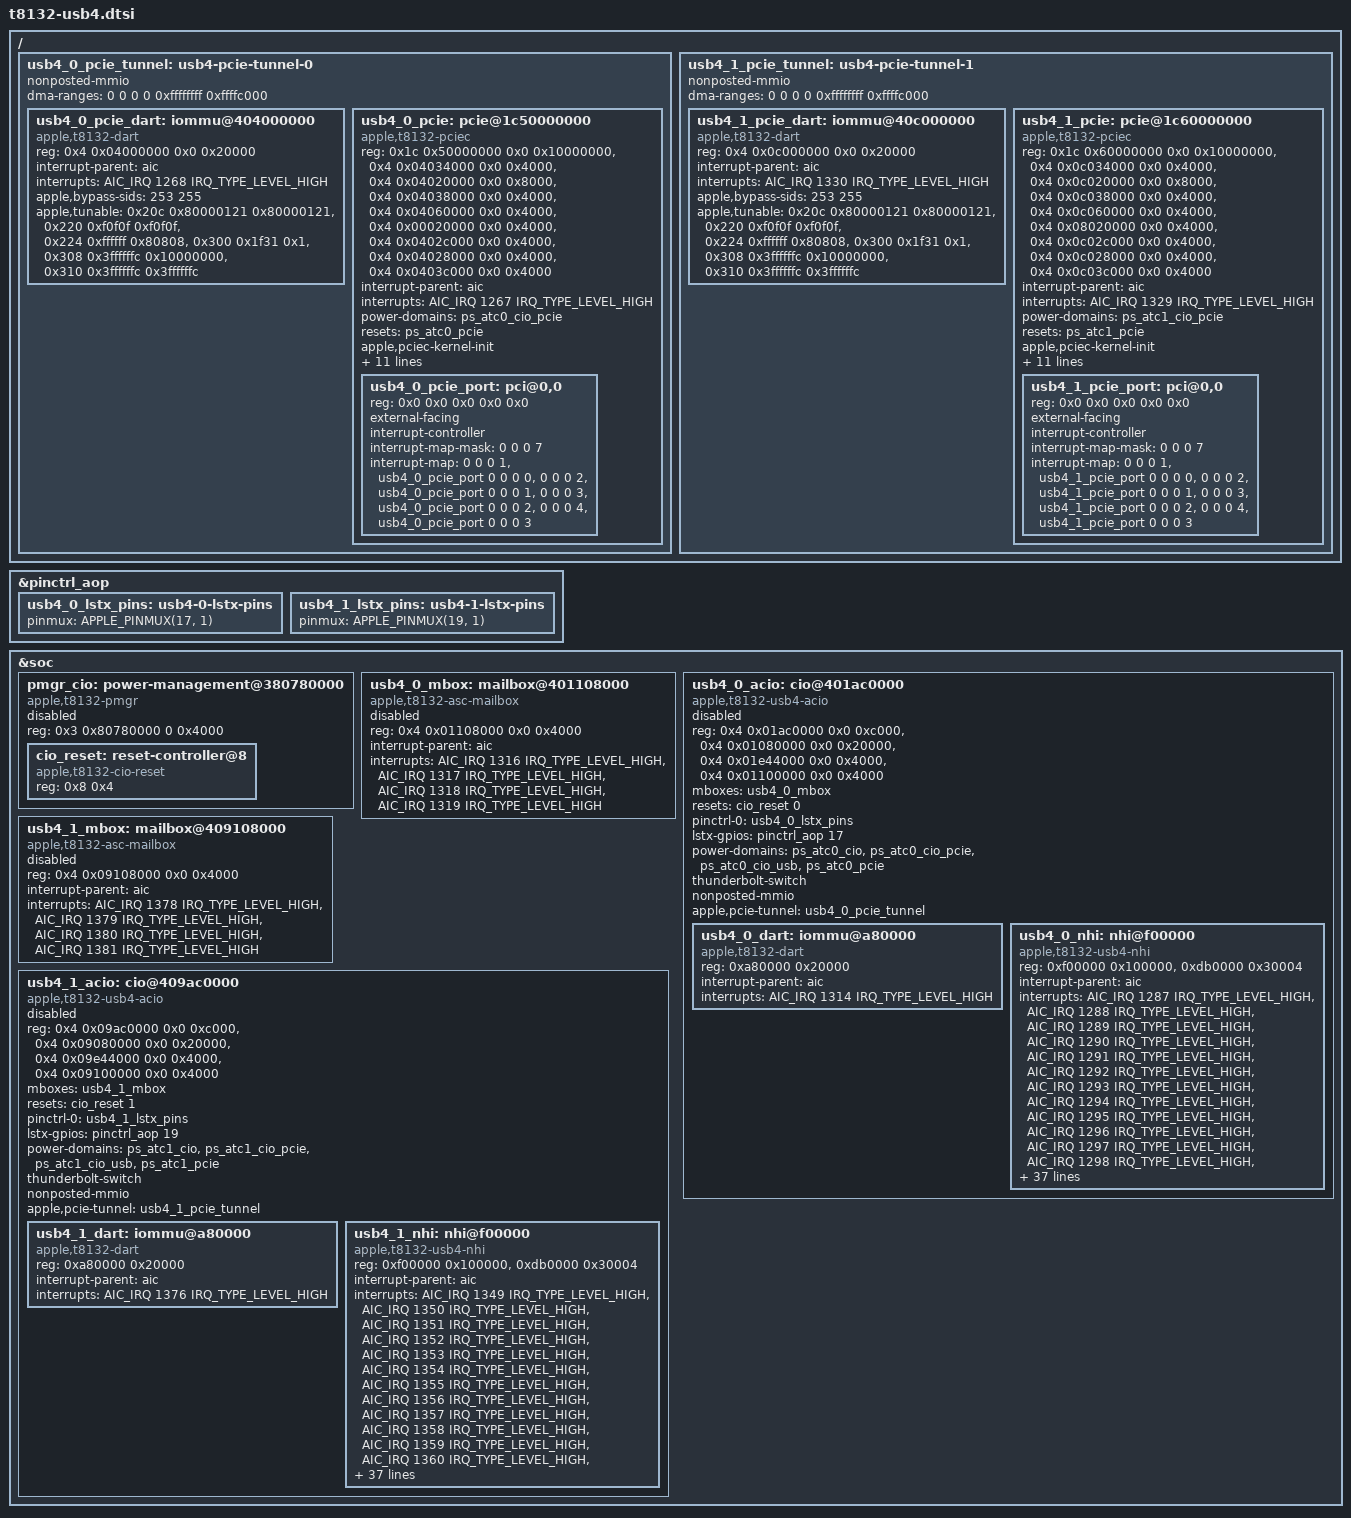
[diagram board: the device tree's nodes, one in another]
// SPDX-License-Identifier: GPL-2.0+ OR MIT
/*
 * Apple T8132 (M4) USB4/Thunderbolt host routers: ACIO0 behind ATC0, ACIO1 behind ATC1.
 *
 * The layout follows T6030: the same offsets from the ACIO base for the rc, sram,
 * PCIe adapter, MxWrap CPU, mailbox, DART and NHI blocks. ACIO1 sits 0x8000000 above
 * ACIO0 and its interrupts 62 above. The NHI ring interrupts are listed tx first
 * (the lower block), then rx.
 *
 * The boot loader fills apple,tunable-rc, -pcie-adapter, -nhi and
 * apple,thunderbolt-drom through the usb4-N-* aliases of the board.
 */

&pinctrl_aop {
	/* LSTX, handed to each router once it is up and held as a GPIO while it is off. */
	usb4_0_lstx_pins: usb4-0-lstx-pins {
		pinmux = <APPLE_PINMUX(17, 1)>;
	};

	usb4_1_lstx_pins: usb4-1-lstx-pins {
		pinmux = <APPLE_PINMUX(19, 1)>;
	};
};

&soc {
	pmgr_cio: power-management@380780000 {
		compatible = "apple,t8132-pmgr", "apple,t8103-pmgr", "syscon", "simple-mfd";
		#address-cells = <1>;
		#size-cells = <1>;
		reg = <0x3 0x80780000 0 0x4000>;
		status = "disabled";

		cio_reset: reset-controller@8 {
			compatible = "apple,t8132-cio-reset", "apple,t6000-cio-reset";
			reg = <0x8 0x4>;
			#reset-cells = <1>;
		};
	};

	usb4_0_mbox: mailbox@401108000 {
		compatible = "apple,t8132-asc-mailbox", "apple,asc-mailbox-v4";
		reg = <0x4 0x01108000 0x0 0x4000>;
		interrupt-parent = <&aic>;
		interrupts = <AIC_IRQ 1316 IRQ_TYPE_LEVEL_HIGH>,
			     <AIC_IRQ 1317 IRQ_TYPE_LEVEL_HIGH>,
			     <AIC_IRQ 1318 IRQ_TYPE_LEVEL_HIGH>,
			     <AIC_IRQ 1319 IRQ_TYPE_LEVEL_HIGH>;
		interrupt-names = "send-empty", "send-not-empty",
				  "recv-empty", "recv-not-empty";
		#mbox-cells = <0>;
		status = "disabled";
	};

	usb4_0_acio: cio@401ac0000 {
		compatible = "apple,t8132-usb4-acio", "apple,t8103-usb4-acio";
		reg = <0x4 0x01ac0000 0x0 0xc000>,
		      <0x4 0x01080000 0x0 0x20000>,
		      <0x4 0x01e44000 0x0 0x4000>,
		      <0x4 0x01100000 0x0 0x4000>;
		reg-names = "rc", "sram", "pcie-adapter", "cpu";

		mboxes = <&usb4_0_mbox>;
		resets = <&cio_reset 0>;
		pinctrl-names = "lstx";
		pinctrl-0 = <&usb4_0_lstx_pins>;
		lstx-gpios = <&pinctrl_aop 17 GPIO_ACTIVE_HIGH>;

		power-domains = <&ps_atc0_cio>,
				<&ps_atc0_cio_pcie>,
				<&ps_atc0_cio_usb>;

		thunderbolt-switch;

		#address-cells = <1>;
		#size-cells = <1>;
		ranges = <0x0 0x4 0x01000000 0x1000000>;
		nonposted-mmio;
		status = "disabled";

		usb4_0_dart: iommu@a80000 {
			compatible = "apple,t8132-dart", "apple,t8110-dart";
			reg = <0xa80000 0x20000>;
			interrupt-parent = <&aic>;
			interrupts = <AIC_IRQ 1314 IRQ_TYPE_LEVEL_HIGH>;
			#iommu-cells = <5>;
		};

		usb4_0_nhi: nhi@f00000 {
			compatible = "apple,t8132-usb4-nhi", "apple,t8103-usb4-nhi";
			reg = <0xf00000 0x100000>,
			      <0xdb0000 0x30004>;
			reg-names = "nhi", "pdf";
			interrupt-parent = <&aic>;
			interrupts = <AIC_IRQ 1287 IRQ_TYPE_LEVEL_HIGH>,
				     <AIC_IRQ 1288 IRQ_TYPE_LEVEL_HIGH>,
				     <AIC_IRQ 1289 IRQ_TYPE_LEVEL_HIGH>,
				     <AIC_IRQ 1290 IRQ_TYPE_LEVEL_HIGH>,
				     <AIC_IRQ 1291 IRQ_TYPE_LEVEL_HIGH>,
				     <AIC_IRQ 1292 IRQ_TYPE_LEVEL_HIGH>,
				     <AIC_IRQ 1293 IRQ_TYPE_LEVEL_HIGH>,
				     <AIC_IRQ 1294 IRQ_TYPE_LEVEL_HIGH>,
				     <AIC_IRQ 1295 IRQ_TYPE_LEVEL_HIGH>,
				     <AIC_IRQ 1296 IRQ_TYPE_LEVEL_HIGH>,
				     <AIC_IRQ 1297 IRQ_TYPE_LEVEL_HIGH>,
				     <AIC_IRQ 1298 IRQ_TYPE_LEVEL_HIGH>,
				     <AIC_IRQ 1299 IRQ_TYPE_LEVEL_HIGH>,
				     <AIC_IRQ 1300 IRQ_TYPE_LEVEL_HIGH>,
				     <AIC_IRQ 1301 IRQ_TYPE_LEVEL_HIGH>,
				     <AIC_IRQ 1302 IRQ_TYPE_LEVEL_HIGH>,
				     <AIC_IRQ 1303 IRQ_TYPE_LEVEL_HIGH>,
				     <AIC_IRQ 1304 IRQ_TYPE_LEVEL_HIGH>,
				     <AIC_IRQ 1305 IRQ_TYPE_LEVEL_HIGH>,
				     <AIC_IRQ 1306 IRQ_TYPE_LEVEL_HIGH>,
				     <AIC_IRQ 1307 IRQ_TYPE_LEVEL_HIGH>,
				     <AIC_IRQ 1308 IRQ_TYPE_LEVEL_HIGH>,
				     <AIC_IRQ 1309 IRQ_TYPE_LEVEL_HIGH>,
				     <AIC_IRQ 1310 IRQ_TYPE_LEVEL_HIGH>;
			interrupt-names =
				"txring0", "txring1", "txring2",
				"txring3", "txring4", "txring5",
				"txring6", "txring7", "txring8",
				"txring9", "txring10", "txring11",
				"rxring0", "rxring1", "rxring2",
				"rxring3", "rxring4", "rxring5",
				"rxring6", "rxring7", "rxring8",
				"rxring9", "rxring10", "rxring11";
			iommus = <&usb4_0_dart 0 0x100 0x0 0x10 0x0>,
				 <&usb4_0_dart 1 0x100 0x0 0x10 0x0>,
				 <&usb4_0_dart 2 0x100 0x0 0x10 0x0>,
				 <&usb4_0_dart 3 0x100 0x0 0x10 0x0>,
				 <&usb4_0_dart 4 0x100 0x0 0x10 0x0>,
				 <&usb4_0_dart 5 0x100 0x0 0x10 0x0>,
				 <&usb4_0_dart 6 0x100 0x0 0x10 0x0>,
				 <&usb4_0_dart 7 0x100 0x0 0x10 0x0>,
				 <&usb4_0_dart 8 0x100 0x0 0x10 0x0>,
				 <&usb4_0_dart 9 0x100 0x0 0x10 0x0>,
				 <&usb4_0_dart 10 0x100 0x0 0x10 0x0>,
				 <&usb4_0_dart 11 0x100 0x0 0x10 0x0>,
				 <&usb4_0_dart 16 0x100 0x0 0x10 0x0>,
				 <&usb4_0_dart 17 0x100 0x0 0x10 0x0>,
				 <&usb4_0_dart 18 0x100 0x0 0x10 0x0>,
				 <&usb4_0_dart 19 0x100 0x0 0x10 0x0>,
				 <&usb4_0_dart 20 0x100 0x0 0x10 0x0>,
				 <&usb4_0_dart 21 0x100 0x0 0x10 0x0>,
				 <&usb4_0_dart 22 0x100 0x0 0x10 0x0>,
				 <&usb4_0_dart 23 0x100 0x0 0x10 0x0>,
				 <&usb4_0_dart 24 0x100 0x0 0x10 0x0>,
				 <&usb4_0_dart 25 0x100 0x0 0x10 0x0>,
				 <&usb4_0_dart 26 0x100 0x0 0x10 0x0>,
				 <&usb4_0_dart 27 0x100 0x0 0x10 0x0>;
			/* To be filled by the loader */
			apple,thunderbolt-drom = [00];
		};
	};

	usb4_1_mbox: mailbox@409108000 {
		compatible = "apple,t8132-asc-mailbox", "apple,asc-mailbox-v4";
		reg = <0x4 0x09108000 0x0 0x4000>;
		interrupt-parent = <&aic>;
		interrupts = <AIC_IRQ 1378 IRQ_TYPE_LEVEL_HIGH>,
			     <AIC_IRQ 1379 IRQ_TYPE_LEVEL_HIGH>,
			     <AIC_IRQ 1380 IRQ_TYPE_LEVEL_HIGH>,
			     <AIC_IRQ 1381 IRQ_TYPE_LEVEL_HIGH>;
		interrupt-names = "send-empty", "send-not-empty",
				  "recv-empty", "recv-not-empty";
		#mbox-cells = <0>;
		status = "disabled";
	};

	usb4_1_acio: cio@409ac0000 {
		compatible = "apple,t8132-usb4-acio", "apple,t8103-usb4-acio";
		reg = <0x4 0x09ac0000 0x0 0xc000>,
		      <0x4 0x09080000 0x0 0x20000>,
		      <0x4 0x09e44000 0x0 0x4000>,
		      <0x4 0x09100000 0x0 0x4000>;
		reg-names = "rc", "sram", "pcie-adapter", "cpu";

		mboxes = <&usb4_1_mbox>;
		resets = <&cio_reset 1>;
		pinctrl-names = "lstx";
		pinctrl-0 = <&usb4_1_lstx_pins>;
		lstx-gpios = <&pinctrl_aop 19 GPIO_ACTIVE_HIGH>;

		power-domains = <&ps_atc1_cio>,
				<&ps_atc1_cio_pcie>,
				<&ps_atc1_cio_usb>;

		thunderbolt-switch;

		#address-cells = <1>;
		#size-cells = <1>;
		ranges = <0x0 0x4 0x09000000 0x1000000>;
		nonposted-mmio;
		status = "disabled";

		usb4_1_dart: iommu@a80000 {
			compatible = "apple,t8132-dart", "apple,t8110-dart";
			reg = <0xa80000 0x20000>;
			interrupt-parent = <&aic>;
			interrupts = <AIC_IRQ 1376 IRQ_TYPE_LEVEL_HIGH>;
			#iommu-cells = <5>;
		};

		usb4_1_nhi: nhi@f00000 {
			compatible = "apple,t8132-usb4-nhi", "apple,t8103-usb4-nhi";
			reg = <0xf00000 0x100000>,
			      <0xdb0000 0x30004>;
			reg-names = "nhi", "pdf";
			interrupt-parent = <&aic>;
			interrupts = <AIC_IRQ 1349 IRQ_TYPE_LEVEL_HIGH>,
				     <AIC_IRQ 1350 IRQ_TYPE_LEVEL_HIGH>,
				     <AIC_IRQ 1351 IRQ_TYPE_LEVEL_HIGH>,
				     <AIC_IRQ 1352 IRQ_TYPE_LEVEL_HIGH>,
				     <AIC_IRQ 1353 IRQ_TYPE_LEVEL_HIGH>,
				     <AIC_IRQ 1354 IRQ_TYPE_LEVEL_HIGH>,
				     <AIC_IRQ 1355 IRQ_TYPE_LEVEL_HIGH>,
				     <AIC_IRQ 1356 IRQ_TYPE_LEVEL_HIGH>,
				     <AIC_IRQ 1357 IRQ_TYPE_LEVEL_HIGH>,
				     <AIC_IRQ 1358 IRQ_TYPE_LEVEL_HIGH>,
				     <AIC_IRQ 1359 IRQ_TYPE_LEVEL_HIGH>,
				     <AIC_IRQ 1360 IRQ_TYPE_LEVEL_HIGH>,
				     <AIC_IRQ 1361 IRQ_TYPE_LEVEL_HIGH>,
				     <AIC_IRQ 1362 IRQ_TYPE_LEVEL_HIGH>,
				     <AIC_IRQ 1363 IRQ_TYPE_LEVEL_HIGH>,
				     <AIC_IRQ 1364 IRQ_TYPE_LEVEL_HIGH>,
				     <AIC_IRQ 1365 IRQ_TYPE_LEVEL_HIGH>,
				     <AIC_IRQ 1366 IRQ_TYPE_LEVEL_HIGH>,
				     <AIC_IRQ 1367 IRQ_TYPE_LEVEL_HIGH>,
				     <AIC_IRQ 1368 IRQ_TYPE_LEVEL_HIGH>,
				     <AIC_IRQ 1369 IRQ_TYPE_LEVEL_HIGH>,
				     <AIC_IRQ 1370 IRQ_TYPE_LEVEL_HIGH>,
				     <AIC_IRQ 1371 IRQ_TYPE_LEVEL_HIGH>,
				     <AIC_IRQ 1372 IRQ_TYPE_LEVEL_HIGH>;
			interrupt-names =
				"txring0", "txring1", "txring2",
				"txring3", "txring4", "txring5",
				"txring6", "txring7", "txring8",
				"txring9", "txring10", "txring11",
				"rxring0", "rxring1", "rxring2",
				"rxring3", "rxring4", "rxring5",
				"rxring6", "rxring7", "rxring8",
				"rxring9", "rxring10", "rxring11";
			iommus = <&usb4_1_dart 0 0x100 0x0 0x10 0x0>,
				 <&usb4_1_dart 1 0x100 0x0 0x10 0x0>,
				 <&usb4_1_dart 2 0x100 0x0 0x10 0x0>,
				 <&usb4_1_dart 3 0x100 0x0 0x10 0x0>,
				 <&usb4_1_dart 4 0x100 0x0 0x10 0x0>,
				 <&usb4_1_dart 5 0x100 0x0 0x10 0x0>,
				 <&usb4_1_dart 6 0x100 0x0 0x10 0x0>,
				 <&usb4_1_dart 7 0x100 0x0 0x10 0x0>,
				 <&usb4_1_dart 8 0x100 0x0 0x10 0x0>,
				 <&usb4_1_dart 9 0x100 0x0 0x10 0x0>,
				 <&usb4_1_dart 10 0x100 0x0 0x10 0x0>,
				 <&usb4_1_dart 11 0x100 0x0 0x10 0x0>,
				 <&usb4_1_dart 16 0x100 0x0 0x10 0x0>,
				 <&usb4_1_dart 17 0x100 0x0 0x10 0x0>,
				 <&usb4_1_dart 18 0x100 0x0 0x10 0x0>,
				 <&usb4_1_dart 19 0x100 0x0 0x10 0x0>,
				 <&usb4_1_dart 20 0x100 0x0 0x10 0x0>,
				 <&usb4_1_dart 21 0x100 0x0 0x10 0x0>,
				 <&usb4_1_dart 22 0x100 0x0 0x10 0x0>,
				 <&usb4_1_dart 23 0x100 0x0 0x10 0x0>,
				 <&usb4_1_dart 24 0x100 0x0 0x10 0x0>,
				 <&usb4_1_dart 25 0x100 0x0 0x10 0x0>,
				 <&usb4_1_dart 26 0x100 0x0 0x10 0x0>,
				 <&usb4_1_dart 27 0x100 0x0 0x10 0x0>;
			/* To be filled by the loader */
			apple,thunderbolt-drom = [00];
		};
	};
};

/*
 * The USB4 PCIe tunnels: one PCIe-C root port per host router, with the DART
 * beside it. ACIO populates each container once the router has a PCIe tunnel,
 * and the kernel cold-initializes the port (apple,pciec-kernel-init).
 *
 * The calibration is in t8132-pciec-tunables.dtsi. The oe-fabric block and
 * its tunable belong to the port's PIO-DMA engine in the ADT, which no
 * bootloader passes on, so they are described here.
 */
/ {
	usb4_0_pcie_tunnel: usb4-pcie-tunnel-0 {
		#address-cells = <2>;
		#size-cells = <2>;
		ranges;
		nonposted-mmio;
		/* Preserve the SoC DMA window after moving the virtual container. */
		dma-ranges = <0 0 0 0 0xffffffff 0xffffc000>;

		usb4_0_pcie_dart: iommu@404000000 {
			compatible = "apple,t8132-dart", "apple,t8110-dart";
			reg = <0x4 0x04000000 0x0 0x20000>;
			interrupt-parent = <&aic>;
			interrupts = <AIC_IRQ 1268 IRQ_TYPE_LEVEL_HIGH>;
			#iommu-cells = <1>;
			/* The port's own writes, MSIs included, use these streams. */
			apple,bypass-sids = <253 255>;
			/* No bootloader fills this one; the tunnel's cold init needs it. */
			apple,tunable =
				<0x20c 0x80000121 0x80000121>,
				<0x220 0xf0f0f 0xf0f0f>,
				<0x224 0xffffff 0x80808>,
				<0x300 0x1f31 0x1>,
				<0x308 0x3ffffffc 0x10000000>,
				<0x310 0x3ffffffc 0x3ffffffc>;
		};

		usb4_0_pcie: pcie@1c50000000 {
			compatible = "apple,t8132-pciec", "apple,t8122-pciec",
				     "apple,t8103-pciec";
			device_type = "pci";
			reg = <0x1c 0x50000000 0x0 0x10000000>,
			      <0x4 0x04034000 0x0 0x4000>,
			      <0x4 0x04020000 0x0 0x8000>,
			      <0x4 0x04038000 0x0 0x4000>,
			      <0x4 0x04060000 0x0 0x4000>,
			      <0x4 0x00020000 0x0 0x4000>,
			      <0x4 0x0402c000 0x0 0x4000>,
			      <0x4 0x04028000 0x0 0x4000>,
			      <0x4 0x0403c000 0x0 0x4000>;
			reg-names = "config", "rc", "port0", "fabric",
				    "debug", "ioa", "ltssm", "intr2axi",
				    "oe-fabric";
			interrupt-parent = <&aic>;
			interrupts = <AIC_IRQ 1267 IRQ_TYPE_LEVEL_HIGH>;
			power-domains = <&ps_atc0_cio_pcie>;
			resets = <&ps_atc0_pcie>;
			apple,pciec-kernel-init;
			apple,tunable-oe-fabric =
				<0x4 0x70007 0x40004>,
				<0xc 0x1 0x1>,
				<0x10 0x1 0x1>,
				<0x14 0x801f 0x4>,
				<0x1c 0x801f 0x4>,
				<0x24 0x801f 0x4>;
			msi-controller;
			msi-parent = <&usb4_0_pcie>;
			/* The ADT bridge's 32-vector slice of the window shared with apcie. */
			msi-ranges = <&aic AIC_IRQ 1602 IRQ_TYPE_EDGE_RISING 32>;
			apple,msi-vector-base = <0x60>;
			iommu-map = <0x0 &usb4_0_pcie_dart 0x0 0x40>;
			iommu-map-mask = <0x3f>;
			bus-range = <0x0 0x7f>;
			#address-cells = <3>;
			#size-cells = <2>;
			ranges = <0x43000000 0x8 0x0
				  0x8 0x0 0x2 0x0>,
				 <0x02000000 0x0 0x100000
				  0xa 0x100000 0x0 0x3ff00000>,
				 <0x42000000 0x0 0x40000000
				  0xa 0x40000000 0x0 0x40000000>;

			usb4_0_pcie_port: pci@0,0 {
				device_type = "pci";
				reg = <0x0 0x0 0x0 0x0 0x0>;
				external-facing;
				/* apple,tunable is filled by the bootloader */
				#address-cells = <3>;
				#size-cells = <2>;
				ranges;
				interrupt-controller;
				#interrupt-cells = <1>;
				interrupt-map-mask = <0 0 0 7>;
				interrupt-map = <0 0 0 1 &usb4_0_pcie_port 0 0 0 0>,
						<0 0 0 2 &usb4_0_pcie_port 0 0 0 1>,
						<0 0 0 3 &usb4_0_pcie_port 0 0 0 2>,
						<0 0 0 4 &usb4_0_pcie_port 0 0 0 3>;
			};
		};
	};

	usb4_1_pcie_tunnel: usb4-pcie-tunnel-1 {
		#address-cells = <2>;
		#size-cells = <2>;
		ranges;
		nonposted-mmio;
		/* Preserve the SoC DMA window after moving the virtual container. */
		dma-ranges = <0 0 0 0 0xffffffff 0xffffc000>;

		usb4_1_pcie_dart: iommu@40c000000 {
			compatible = "apple,t8132-dart", "apple,t8110-dart";
			reg = <0x4 0x0c000000 0x0 0x20000>;
			interrupt-parent = <&aic>;
			interrupts = <AIC_IRQ 1330 IRQ_TYPE_LEVEL_HIGH>;
			#iommu-cells = <1>;
			/* The port's own writes, MSIs included, use these streams. */
			apple,bypass-sids = <253 255>;
			/* No bootloader fills this one; the tunnel's cold init needs it. */
			apple,tunable =
				<0x20c 0x80000121 0x80000121>,
				<0x220 0xf0f0f 0xf0f0f>,
				<0x224 0xffffff 0x80808>,
				<0x300 0x1f31 0x1>,
				<0x308 0x3ffffffc 0x10000000>,
				<0x310 0x3ffffffc 0x3ffffffc>;
		};

		usb4_1_pcie: pcie@1c60000000 {
			compatible = "apple,t8132-pciec", "apple,t8122-pciec",
				     "apple,t8103-pciec";
			device_type = "pci";
			reg = <0x1c 0x60000000 0x0 0x10000000>,
			      <0x4 0x0c034000 0x0 0x4000>,
			      <0x4 0x0c020000 0x0 0x8000>,
			      <0x4 0x0c038000 0x0 0x4000>,
			      <0x4 0x0c060000 0x0 0x4000>,
			      <0x4 0x08020000 0x0 0x4000>,
			      <0x4 0x0c02c000 0x0 0x4000>,
			      <0x4 0x0c028000 0x0 0x4000>,
			      <0x4 0x0c03c000 0x0 0x4000>;
			reg-names = "config", "rc", "port0", "fabric",
				    "debug", "ioa", "ltssm", "intr2axi",
				    "oe-fabric";
			interrupt-parent = <&aic>;
			interrupts = <AIC_IRQ 1329 IRQ_TYPE_LEVEL_HIGH>;
			power-domains = <&ps_atc1_cio_pcie>;
			resets = <&ps_atc1_pcie>;
			apple,pciec-kernel-init;
			apple,tunable-oe-fabric =
				<0x4 0x70007 0x40004>,
				<0xc 0x1 0x1>,
				<0x10 0x1 0x1>,
				<0x14 0x801f 0x4>,
				<0x1c 0x801f 0x4>,
				<0x24 0x801f 0x4>;
			msi-controller;
			msi-parent = <&usb4_1_pcie>;
			/* The ADT bridge's 32-vector slice of the window shared with apcie. */
			msi-ranges = <&aic AIC_IRQ 1634 IRQ_TYPE_EDGE_RISING 32>;
			apple,msi-vector-base = <0x80>;
			iommu-map = <0x0 &usb4_1_pcie_dart 0x0 0x40>;
			iommu-map-mask = <0x3f>;
			bus-range = <0x0 0x7f>;
			#address-cells = <3>;
			#size-cells = <2>;
			ranges = <0x43000000 0xc 0x0
				  0xc 0x0 0x2 0x0>,
				 <0x02000000 0x0 0x100000
				  0xe 0x100000 0x0 0x3ff00000>,
				 <0x42000000 0x0 0x40000000
				  0xe 0x40000000 0x0 0x40000000>;

			usb4_1_pcie_port: pci@0,0 {
				device_type = "pci";
				reg = <0x0 0x0 0x0 0x0 0x0>;
				external-facing;
				/* apple,tunable is filled by the bootloader */
				#address-cells = <3>;
				#size-cells = <2>;
				ranges;
				interrupt-controller;
				#interrupt-cells = <1>;
				interrupt-map-mask = <0 0 0 7>;
				interrupt-map = <0 0 0 1 &usb4_1_pcie_port 0 0 0 0>,
						<0 0 0 2 &usb4_1_pcie_port 0 0 0 1>,
						<0 0 0 3 &usb4_1_pcie_port 0 0 0 2>,
						<0 0 0 4 &usb4_1_pcie_port 0 0 0 3>;
			};
		};
	};
};

&usb4_0_acio {
	power-domains = <&ps_atc0_cio>, <&ps_atc0_cio_pcie>,
			<&ps_atc0_cio_usb>, <&ps_atc0_pcie>;
	apple,pcie-tunnel = <&usb4_0_pcie_tunnel>;
};

&usb4_1_acio {
	power-domains = <&ps_atc1_cio>, <&ps_atc1_cio_pcie>,
			<&ps_atc1_cio_usb>, <&ps_atc1_pcie>;
	apple,pcie-tunnel = <&usb4_1_pcie_tunnel>;
};
